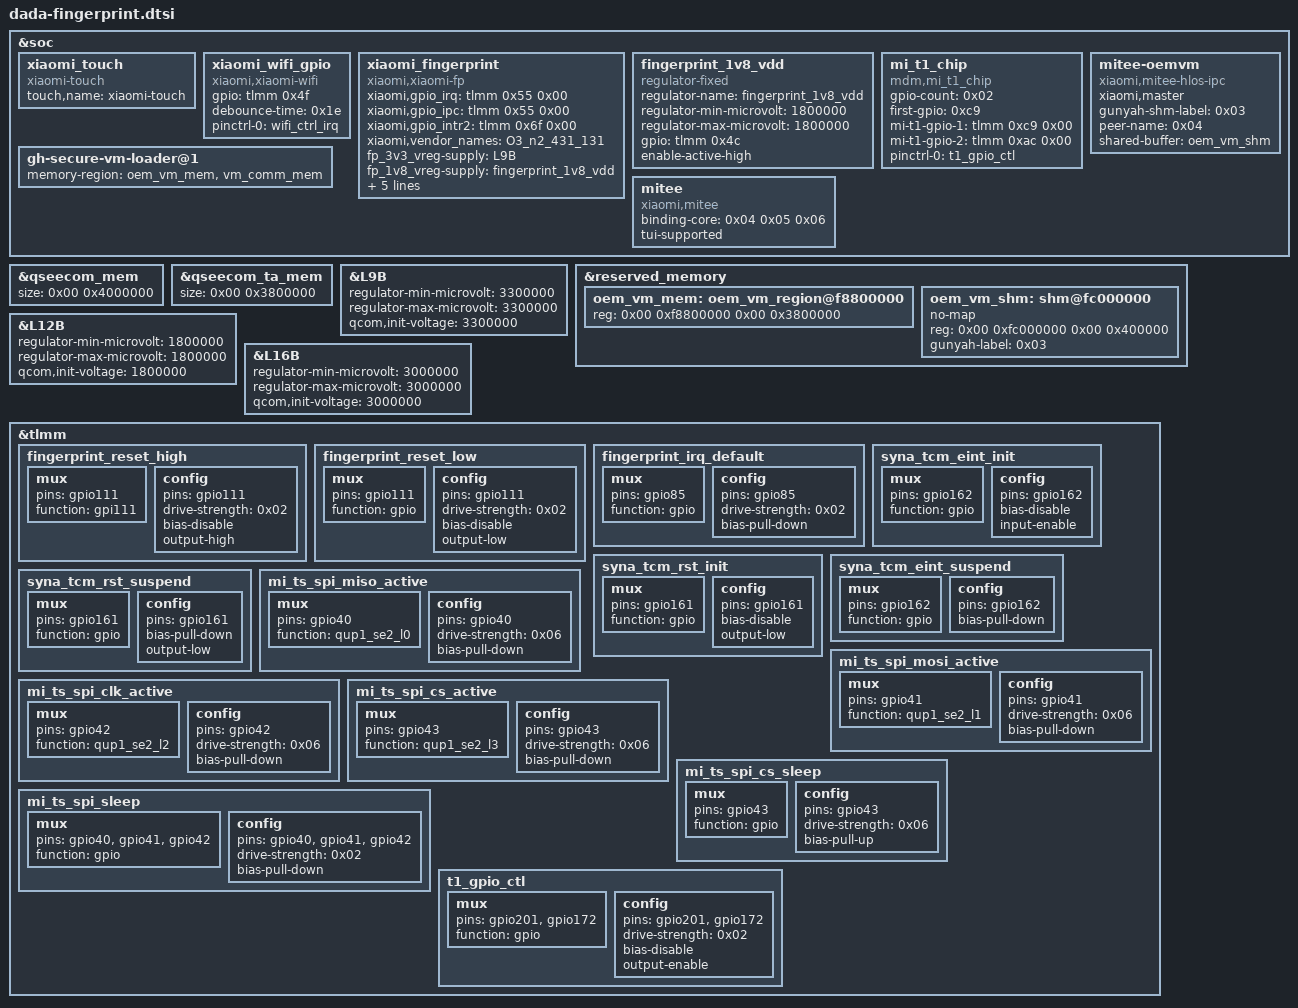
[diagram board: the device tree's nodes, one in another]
// SPDX-License-Identifier: BSD-3-Clause
/*
 * Copyright (c) 2023-2024 Qualcomm Innovation Center, Inc. All rights reserved.
 * Copyright (c) 2025 The LineageOS Project
 */

&soc {
	xiaomi_touch {
		compatible = "xiaomi-touch";
		status = "ok";
		touch,name = "xiaomi-touch";
	};

	xiaomi_wifi_gpio {
		compatible = "xiaomi,xiaomi-wifi";
		gpio = <&tlmm 0x4f 0x00>;
		debounce-time = <0x1e>;
		pinctrl-names = "default";
		pinctrl-0 = <&wifi_ctrl_irq>;
		status = "ok";
	};

	xiaomi_fingerprint {
		compatible = "xiaomi,xiaomi-fp";
		xiaomi,gpio_irq = <&tlmm 0x55 0x00>;
		xiaomi,gpio_ipc = <&tlmm 0x55 0x00>;
		xiaomi,gpio_intr2 = <&tlmm 0x6f 0x00>;
		xiaomi,vendor_names = "O3_n2_431_131";
		fp_3v3_vreg-supply = <&L9B>;
		fp_1v8_vreg-supply = <&fingerprint_1v8_vdd>;
		netlink-event = <0x19>;
		sensor-loc = <0x1e0 0x772 0x2cf 0x875>;
		pinctrl-names = "reset_high", "reset_low", "irq_default";
		pinctrl-0 = <&fingerprint_reset_high>;
		pinctrl-1 = <&fingerprint_reset_low>;
		pinctrl-2 = <&fingerprint_irq_default>;
		status = "ok";
	};

	fingerprint_1v8_vdd: fingerprint_1v8_vdd {
		compatible = "regulator-fixed";
		regulator-name = "fingerprint_1v8_vdd";
		regulator-min-microvolt = <1800000>;
		regulator-max-microvolt = <1800000>;
		gpio = <&tlmm 0x4c 0x00>;
		enable-active-high;
	};

	mi_t1_chip {
		compatible = "mdm,mi_t1_chip";
		gpio-count = <0x02>;
		first-gpio = <0xc9>;
		mi-t1-gpio-1 = <&tlmm 0xc9 0x00>;
		mi-t1-gpio-2 = <&tlmm 0xac 0x00>;
		pinctrl-0 = <&t1_gpio_ctl>;
	};
};

&qseecom_mem {
	size = <0x00 0x4000000>;
};

&qseecom_ta_mem {
	size = <0x00 0x3800000>;
};

&L9B {
	regulator-min-microvolt = <3300000>;
	regulator-max-microvolt = <3300000>;
	qcom,init-voltage = <3300000>;
};

&reserved_memory {
	oem_vm_mem: oem_vm_region@f8800000 {
		reg = <0x00 0xf8800000 0x00 0x3800000>;
	};

	oem_vm_shm: shm@fc000000 {
		no-map;
		reg = <0x00 0xfc000000 0x00 0x400000>;
		gunyah-label = <0x03>;
	};
};

&soc {
	gh-secure-vm-loader@1 {
		memory-region = <&oem_vm_mem &vm_comm_mem>;
	};

	mitee: mitee {
		compatible = "xiaomi,mitee";
		binding-core = <0x04 0x05 0x06>;
		tui-supported;
	};

	mitee-oemvm {
		compatible = "xiaomi,mitee-hlos-ipc";
		xiaomi,master;
		gunyah-shm-label = <0x03>;
		peer-name = <0x04>;
		shared-buffer = <&oem_vm_shm>;
	};
};

&L12B {
	regulator-min-microvolt = <1800000>;
	regulator-max-microvolt = <1800000>;
	qcom,init-voltage = <1800000>;
};

&L16B {
	regulator-min-microvolt = <3000000>;
	regulator-max-microvolt = <3000000>;
	qcom,init-voltage = <3000000>;
};

&tlmm {
	fingerprint_reset_high: fingerprint_reset_high {

		mux {
			pins = "gpio111";
			function = "gpi111";
		};

		config {
			pins = "gpio111";
			drive-strength = <0x02>;
			bias-disable;
			output-high;
		};
	};

	fingerprint_reset_low: fingerprint_reset_low {

		mux {
			pins = "gpio111";
			function = "gpio";
		};

		config {
			pins = "gpio111";
			drive-strength = <0x02>;
			bias-disable;
			output-low;
		};
	};

	fingerprint_irq_default: fingerprint_irq_default {

		mux {
			pins = "gpio85";
			function = "gpio";
		};

		config {
			pins = "gpio85";
			drive-strength = <0x02>;
			bias-pull-down;
		};
	};

	syna_tcm_eint_init: syna_tcm_eint_init {

		mux {
			pins = "gpio162";
			function = "gpio";
		};

		config {
			pins = "gpio162";
			bias-disable;
			input-enable;
		};
	};

	syna_tcm_rst_init: syna_tcm_rst_init {

		mux {
			pins = "gpio161";
			function = "gpio";
		};

		config {
			pins = "gpio161";
			bias-disable;
			output-low;
		};
	};

	syna_tcm_eint_suspend: syna_tcm_eint_suspend {

		mux {
			pins = "gpio162";
			function = "gpio";
		};

		config {
			pins = "gpio162";
			bias-pull-down;
		};
	};

	syna_tcm_rst_suspend: syna_tcm_rst_suspend {

		mux {
			pins = "gpio161";
			function = "gpio";
		};

		config {
			pins = "gpio161";
			bias-pull-down;
			output-low;
		};
	};

	mi_ts_spi_miso_active: mi_ts_spi_miso_active {

		mux {
			pins = "gpio40";
			function = "qup1_se2_l0";
		};

		config {
			pins = "gpio40";
			drive-strength = <0x06>;
			bias-pull-down;
		};
	};

	mi_ts_spi_mosi_active: mi_ts_spi_mosi_active {

		mux {
			pins = "gpio41";
			function = "qup1_se2_l1";
		};

		config {
			pins = "gpio41";
			drive-strength = <0x06>;
			bias-pull-down;
		};
	};

	mi_ts_spi_clk_active: mi_ts_spi_clk_active {

		mux {
			pins = "gpio42";
			function = "qup1_se2_l2";
		};

		config {
			pins = "gpio42";
			drive-strength = <0x06>;
			bias-pull-down;
		};
	};

	mi_ts_spi_cs_active: mi_ts_spi_cs_active {

		mux {
			pins = "gpio43";
			function = "qup1_se2_l3";
		};

		config {
			pins = "gpio43";
			drive-strength = <0x06>;
			bias-pull-down;
		};
	};

	mi_ts_spi_cs_sleep: mi_ts_spi_cs_sleep {

		mux {
			pins = "gpio43";
			function = "gpio";
		};

		config {
			pins = "gpio43";
			drive-strength = <0x06>;
			bias-pull-up;
		};
	};

	mi_ts_spi_sleep: mi_ts_spi_sleep {

		mux {
			pins = "gpio40", "gpio41", "gpio42";
			function = "gpio";
		};

		config {
			pins = "gpio40", "gpio41", "gpio42";
			drive-strength = <0x02>;
			bias-pull-down;
		};
	};

	t1_gpio_ctl: t1_gpio_ctl {

		mux {
			pins = "gpio201", "gpio172";
			function = "gpio";
		};

		config {
			pins = "gpio201", "gpio172";
			drive-strength = <0x02>;
			bias-disable;
			output-enable;
		};
	};
};
